AUTOSAR XML (schema 4-2-2)
package /Components
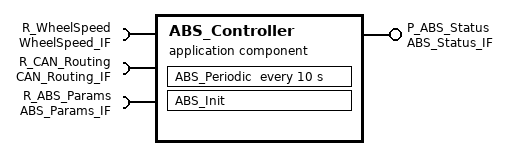
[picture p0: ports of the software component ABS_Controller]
  application sw component type ABS_Controller
    provide port P_ABS_Status: provided-interface=ABS_Status_IF
    require port R_WheelSpeed: required-interface=WheelSpeed_IF
    require port R_CAN_Routing: required-interface=CAN_Routing_IF
    require port R_ABS_Params: required-interface=ABS_Params_IF
    behavior ABS_Controller_InternalBehavior
      init event ABS_Init_Event: start-on-event=ABS_Init
      timing event ABS_Periodic_Event: start-on-event=ABS_Periodic, period=10
      runnable ABS_Init
        parameter access PA_Init_AbsSlipThreshold: accessed-parameter=R_ABS_Params.abs_slip_threshold
        parameter access PA_Init_AbsGain: accessed-parameter=R_ABS_Params.abs_gain
      runnable ABS_Periodic: minimum-start-interval=10
        data-read-access:
          4 x access:
            VA_Read_WS_FL: accessed-variable=R_WheelSpeed.wheel_speed_fl
            VA_Read_WS_FR: accessed-variable=R_WheelSpeed.wheel_speed_fr
            VA_Read_WS_RL: accessed-variable=R_WheelSpeed.wheel_speed_rl
            VA_Read_WS_RR: accessed-variable=R_WheelSpeed.wheel_speed_rr
        data-send-points:
          access VA_Send_ABS_Active: accessed-variable=P_ABS_Status.abs_active
          access VA_Send_ABS_FaultCode: accessed-variable=P_ABS_Status.abs_fault_code
        sync call SCP_SendABSCommand: operation=R_CAN_Routing.SendABSCommand, timeout=5
